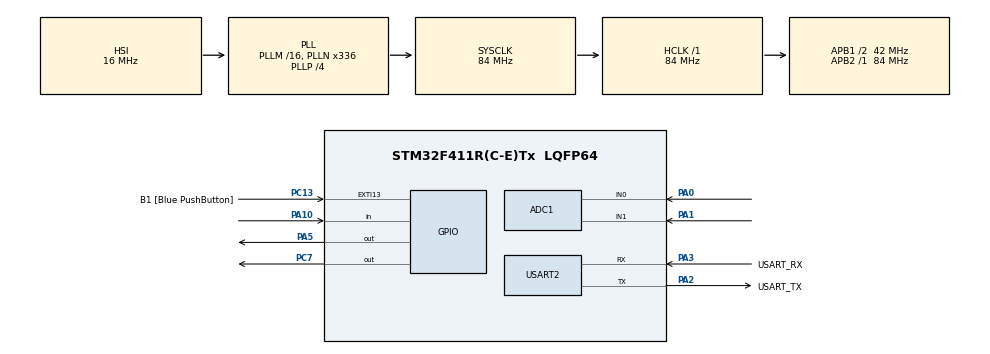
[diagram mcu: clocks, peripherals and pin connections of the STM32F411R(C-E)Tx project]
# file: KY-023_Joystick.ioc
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ADC1.Channel-3\#ChannelRegularConversion=ADC_CHANNEL_1
ADC1.NbrOfConversionFlag=1
ADC1.Rank-3\#ChannelRegularConversion=1
ADC1.SamplingTime-3\#ChannelRegularConversion=ADC_SAMPLETIME_3CYCLES
ADC1.master=1
Mcu.Family=STM32F4
Mcu.Name=STM32F411R(C-E)Tx
Mcu.Package=LQFP64
NVIC.PriorityGroup=NVIC_PRIORITYGROUP_0
PA0-WKUP.Signal=ADCx_IN0
PA1.Signal=ADCx_IN1
PA10.GPIO_PuPd=GPIO_PULLUP
PA10.Signal=GPIO_Input
PA13.GPIO_Label=TMS
PA13.Signal=SYS_JTMS-SWDIO
PA14.GPIO_Label=TCK
PA14.Signal=SYS_JTCK-SWCLK
PA2.GPIO_Label=USART_TX
PA2.Mode=Asynchronous
PA2.Signal=USART2_TX
PA3.GPIO_Label=USART_RX
PA3.Mode=Asynchronous
PA3.Signal=USART2_RX
PA5.Signal=GPIO_Output
PB3.Signal=SYS_JTDO-SWO
PC13-ANTI_TAMP.GPIO_Label=B1 [Blue PushButton]
PC13-ANTI_TAMP.GPIO_ModeDefaultEXTI=GPIO_MODE_IT_FALLING
PC13-ANTI_TAMP.Signal=GPXTI13
PC14-OSC32_IN.Mode=LSE-External-Oscillator
PC14-OSC32_IN.Signal=RCC_OSC32_IN
PC15-OSC32_OUT.Mode=LSE-External-Oscillator
PC15-OSC32_OUT.Signal=RCC_OSC32_OUT
PC7.Signal=GPIO_Output
PH0\ -\ OSC_IN.Mode=HSE-External-Clock-Source
PH0\ -\ OSC_IN.Signal=RCC_OSC_IN
PH1\ -\ OSC_OUT.Mode=HSE-External-Clock-Source
PH1\ -\ OSC_OUT.Signal=RCC_OSC_OUT
ProjectManager.HeapSize=0x200
ProjectManager.StackSize=0x400
ProjectManager.TargetToolchain=STM32CubeIDE
RCC.48MHZClocksFreq_Value=84000000
RCC.AHBFreq_Value=84000000
RCC.APB1CLKDivider=RCC_HCLK_DIV2
RCC.APB1Freq_Value=42000000
RCC.APB1TimFreq_Value=84000000
RCC.APB2Freq_Value=84000000
RCC.APB2TimFreq_Value=84000000
RCC.CortexFreq_Value=84000000
RCC.FLatency-AdvancedSettings=FLASH_LATENCY_2
RCC.HCLKFreq_Value=84000000
RCC.HSE_VALUE=8000000
RCC.HSI_VALUE=16000000
RCC.PLLN=336
RCC.PLLP=RCC_PLLP_DIV4
RCC.SYSCLKFreq_VALUE=84000000
RCC.SYSCLKSource=RCC_SYSCLKSOURCE_PLLCLK
RCC.VCOOutputFreq_Value=336000000
SH.ADCx_IN0.0=ADC1_IN0,IN0
SH.ADCx_IN1.0=ADC1_IN1,IN1
TIM3.Period=999
TIM3.Prescaler=95
USART2.VirtualMode=VM_ASYNC
VP_TIM3_VS_ClockSourceINT.Mode=Internal
board=NUCLEO-F411RE

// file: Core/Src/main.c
/* USER CODE BEGIN Header */
/**
 ******************************************************************************
 * @file           : main.c
 * @brief          : Main program body
 ******************************************************************************
 * @attention
 *
 * Copyright (c) 2026 STMicroelectronics.
 * All rights reserved.
 *
 * This software is licensed under terms that can be found in the LICENSE file
 * in the root directory of this software component.
 * If no LICENSE file comes with this software, it is provided AS-IS.
 *
 ******************************************************************************
 */
/* USER CODE END Header */
#include "main.h"

/* USER CODE BEGIN Includes */
#include <stdio.h>   // Для корректной работы sprintf
#include <stdlib.h>  // Для корректной работы abs
/* USER CODE END Includes */

ADC_HandleTypeDef hadc1;
DMA_HandleTypeDef hdma_adc1;

TIM_HandleTypeDef htim3;

UART_HandleTypeDef huart2;

/* USER CODE BEGIN PV */
extern TIM_HandleTypeDef htim3;

//uint16_t adc_buffer[2];  // Массив: adc_buffer[0] - X, adc_buffer[1] - Y
int32_t x_percent = 0;     // Итоговый процент X (-100...100)
int32_t y_percent = 0;     // Итоговый процент Y (-100...100)
uint8_t btn_state = 0;     // Кнопка
char tx_buf[100];          // Буфер для текста (задали четкий размер)

#define DEADZONE 80        // Мертвая зона
/* USER CODE END PV */

void SystemClock_Config(void);
static void MX_GPIO_Init(void);
static void MX_DMA_Init(void);
static void MX_USART2_UART_Init(void);
static void MX_ADC1_Init(void);
static void MX_TIM3_Init(void);

/* USER CODE BEGIN 0 */

uint32_t Read_ADC_Channel(uint32_t channel) {
	ADC_ChannelConfTypeDef sConfig = { 0 };

	sConfig.Channel = channel;
	sConfig.Rank = 1;
	sConfig.SamplingTime = ADC_SAMPLETIME_84CYCLES;

	// Если конфигурация канала не удалась, просто выходим
	if (HAL_ADC_ConfigChannel(&hadc1, &sConfig) != HAL_OK) {
		return 2048; // Возвращаем центр, чтобы не было ложного прыжка в 100%
	}

	HAL_ADC_Start(&hadc1);
	// Задаем жесткий таймаут в 5 миллисекунд. Если АЦП завис — HAL принудительно вернет управление
	if (HAL_ADC_PollForConversion(&hadc1, 5) == HAL_OK) {
		uint32_t val = HAL_ADC_GetValue(&hadc1);
		HAL_ADC_Stop(&hadc1);
		return val;
	}
	HAL_ADC_Stop(&hadc1);
	return 2048; // Если замер не успел, возвращаем центр
}

/* USER CODE END 0 */

int main(void) {
	/* USER CODE BEGIN 1 */
	// 1. Включаем тактирование Порта C и Таймера 3 напрямую в регистрах
	__HAL_RCC_GPIOC_CLK_ENABLE();
	__HAL_RCC_TIM3_CLK_ENABLE();

	// 2. Переводим пин PC7 в режим альтернативной функции (ШИМ таймера)
	GPIOC->MODER &= ~(3 << (7 * 2)); // Очищаем старый режим
	GPIOC->MODER |= (2 << (7 * 2)); // Устанавливаем режим 10 (Alternate function mode)

	// 3. Указываем, что альтернативная функция для PC7 — это именно TIM3 (AF02)
	GPIOC->AFR[0] &= ~(0xF << (7 * 4)); // Очищаем регистр альтернативных функций для пина 7
	GPIOC->AFR[0] |= (2 << (7 * 4));   // Записываем код AF2 (Таймер TIM3)
	/* USER CODE END 1 */

	/* MCU Configuration--------------------------------------------------------*/

	/* Reset of all peripherals, Initializes the Flash interface and the Systick. */
	HAL_Init();

	/* Configure the system clock */
	SystemClock_Config();

	/* Initialize all configured peripherals */
	MX_GPIO_Init();
	MX_DMA_Init();
	MX_USART2_UART_Init();
	MX_ADC1_Init();
	MX_TIM3_Init();

	/* USER CODE BEGIN 2 */
	HAL_ADC_Start(&hadc1);

	// Запускаем генерацию ШИМ на втором канале таймера 3
//	HAL_TIM_PWM_Start(&htim3, TIM_CHANNEL_1);
	HAL_TIM_PWM_Start(&htim3, TIM_CHANNEL_2);
	/* USER CODE END 2 */

	/* Infinite loop */
	while (1) {

		/* USER CODE BEGIN 3 */
		// Принудительно переводим пин PC7 в режим обычного выхода и включаем его на 100%
		HAL_GPIO_WritePin(GPIOC, GPIO_PIN_7, GPIO_PIN_SET);

		int32_t raw_x = (int32_t) Read_ADC_Channel(ADC_CHANNEL_0) - 2048; // Пин PA0 (A0)
		int32_t raw_y = (int32_t) Read_ADC_Channel(ADC_CHANNEL_1) - 2048; // Пин PA1 (A1)
		int32_t max_range = 2048 - DEADZONE;

		// 2. Расчет процентов оси X
		if (raw_x > -DEADZONE && raw_x < DEADZONE)
			x_percent = 0;
		else if (raw_x >= DEADZONE)
			x_percent = ((raw_x - DEADZONE) * 100) / max_range;
		else
			x_percent = ((raw_x + DEADZONE) * 100) / max_range;

		// 3. Расчет процентов оси Y
		if (raw_y > -DEADZONE && raw_y < DEADZONE)
			y_percent = 0;
		else if (raw_y >= DEADZONE)
			y_percent = ((raw_y - DEADZONE) * 100) / max_range;
		else
			y_percent = ((raw_y + DEADZONE) * 100) / max_range;

		// Жесткое ограничение лимитов [-100, 100] на случай шумов
		if (x_percent > 100)
			x_percent = 100;
		if (x_percent < -100)
			x_percent = -100;
		if (y_percent > 100)
			y_percent = 100;
		if (y_percent < -100)
			y_percent = -100;

		// 4. Опрос кнопки (PA10) и управление встроенным зеленым диодом (оставляем как есть)
		if (HAL_GPIO_ReadPin(GPIOA, GPIO_PIN_10) == GPIO_PIN_RESET) {
			btn_state = 1;
			HAL_GPIO_WritePin(GPIOA, GPIO_PIN_5, GPIO_PIN_SET);
		} else {
			btn_state = 0;
			HAL_GPIO_WritePin(GPIOA, GPIO_PIN_5, GPIO_PIN_RESET);
		}

//		// 5. НАДЕЖНОЕ ПРОГРАММНОЕ УПРАВЛЕНИЕ ВЫЖИВШИМ КРАСНЫМ СВЕТОДИОДОМ
//		// Если джойстик отклонен влево или вправо (по оси X) более чем на 30%
//		if (abs(x_percent) > 30) {
//			// Подаем 3.3В на ножку PC7 — красный светодиод ярко загорается!
//			HAL_GPIO_WritePin(GPIOC, GPIO_PIN_7, GPIO_PIN_SET);
//		} else {
//			// Джойстик в центре (внутри мертвой зоны) — полностью гасим светодиод
//			HAL_GPIO_WritePin(GPIOC, GPIO_PIN_7, GPIO_PIN_RESET);
//		}
//
		// 5. ПЛАВНОЕ УПРАВЛЕНИЕ ШИМ-МОДУЛЕМ (Переводим проценты в яркость)
		// Превращаем проценты оси X (-100...100%) в шаги таймера от 0 до 999
		uint32_t pwm_x = (abs(x_percent) * 999) / 100;

		// Записываем значение в регистр сравнения второго канала таймера (пин PC7)
		__HAL_TIM_SET_COMPARE(&htim3, TIM_CHANNEL_2, pwm_x);

		// 6. Вывод рабочих данных в UART (оставляем как есть)
		int len = sprintf(tx_buf, "X: %4ld%% | Y: %4ld%% | Button: %d\r\n",
				x_percent, y_percent, btn_state);
		HAL_UART_Transmit(&huart2, (uint8_t*) tx_buf, len, HAL_MAX_DELAY);

		HAL_Delay(100);
	}
	/* USER CODE END 3 */

}

void SystemClock_Config(void) {
	RCC_OscInitTypeDef RCC_OscInitStruct = { 0 };
	RCC_ClkInitTypeDef RCC_ClkInitStruct = { 0 };

	/** Configure the main internal regulator output voltage
	 */
	__HAL_RCC_PWR_CLK_ENABLE();
	__HAL_PWR_VOLTAGESCALING_CONFIG(PWR_REGULATOR_VOLTAGE_SCALE1);

	/** Initializes the RCC Oscillators according to the specified parameters
	 * in the RCC_OscInitTypeDef structure.
	 */
	RCC_OscInitStruct.OscillatorType = RCC_OSCILLATORTYPE_HSI;
	RCC_OscInitStruct.HSIState = RCC_HSI_ON;
	RCC_OscInitStruct.HSICalibrationValue = RCC_HSICALIBRATION_DEFAULT;
	RCC_OscInitStruct.PLL.PLLState = RCC_PLL_ON;
	RCC_OscInitStruct.PLL.PLLSource = RCC_PLLSOURCE_HSI;
	RCC_OscInitStruct.PLL.PLLM = 16;
	RCC_OscInitStruct.PLL.PLLN = 336;
	RCC_OscInitStruct.PLL.PLLP = RCC_PLLP_DIV4;
	RCC_OscInitStruct.PLL.PLLQ = 4;
	if (HAL_RCC_OscConfig(&RCC_OscInitStruct) != HAL_OK) {
		Error_Handler();
	}

	/** Initializes the CPU, AHB and APB buses clocks
	 */
	RCC_ClkInitStruct.ClockType = RCC_CLOCKTYPE_HCLK | RCC_CLOCKTYPE_SYSCLK
			| RCC_CLOCKTYPE_PCLK1 | RCC_CLOCKTYPE_PCLK2;
	RCC_ClkInitStruct.SYSCLKSource = RCC_SYSCLKSOURCE_PLLCLK;
	RCC_ClkInitStruct.AHBCLKDivider = RCC_SYSCLK_DIV1;
	RCC_ClkInitStruct.APB1CLKDivider = RCC_HCLK_DIV2;
	RCC_ClkInitStruct.APB2CLKDivider = RCC_HCLK_DIV1;

	if (HAL_RCC_ClockConfig(&RCC_ClkInitStruct, FLASH_LATENCY_2) != HAL_OK) {
		Error_Handler();
	}
}

static void MX_ADC1_Init(void) {

	ADC_ChannelConfTypeDef sConfig = { 0 };

	/** Configure the global features of the ADC (Clock, Resolution, Data Alignment and number of conversion)
	 */
	hadc1.Instance = ADC1;
	hadc1.Init.ClockPrescaler = ADC_CLOCK_SYNC_PCLK_DIV4;
	hadc1.Init.Resolution = ADC_RESOLUTION_12B;
	hadc1.Init.ScanConvMode = ENABLE;
	hadc1.Init.ContinuousConvMode = DISABLE;
	hadc1.Init.DiscontinuousConvMode = DISABLE;
	hadc1.Init.ExternalTrigConvEdge = ADC_EXTERNALTRIGCONVEDGE_NONE;
	hadc1.Init.ExternalTrigConv = ADC_SOFTWARE_START;
	hadc1.Init.DataAlign = ADC_DATAALIGN_RIGHT;
	hadc1.Init.NbrOfConversion = 2;
	hadc1.Init.DMAContinuousRequests = DISABLE;
	hadc1.Init.EOCSelection = ADC_EOC_SINGLE_CONV;
	if (HAL_ADC_Init(&hadc1) != HAL_OK) {
		Error_Handler();
	}

	/** Configure for the selected ADC regular channel its corresponding rank in the sequencer and its sample time.
	 */
	sConfig.Channel = ADC_CHANNEL_0;
	sConfig.Rank = 1;
	sConfig.SamplingTime = ADC_SAMPLETIME_84CYCLES;
	if (HAL_ADC_ConfigChannel(&hadc1, &sConfig) != HAL_OK) {
		Error_Handler();
	}

	/** Configure for the selected ADC regular channel its corresponding rank in the sequencer and its sample time.
	 */
	sConfig.Channel = ADC_CHANNEL_1;
	sConfig.Rank = 2;
	if (HAL_ADC_ConfigChannel(&hadc1, &sConfig) != HAL_OK) {
		Error_Handler();
	}

}

static void MX_TIM3_Init(void) {

	TIM_ClockConfigTypeDef sClockSourceConfig = { 0 };
	TIM_MasterConfigTypeDef sMasterConfig = { 0 };
	TIM_OC_InitTypeDef sConfigOC = { 0 };

	htim3.Instance = TIM3;
	htim3.Init.Prescaler = 95;
	htim3.Init.CounterMode = TIM_COUNTERMODE_UP;
	htim3.Init.Period = 999;
	htim3.Init.ClockDivision = TIM_CLOCKDIVISION_DIV1;
	htim3.Init.AutoReloadPreload = TIM_AUTORELOAD_PRELOAD_DISABLE;
	if (HAL_TIM_Base_Init(&htim3) != HAL_OK) {
		Error_Handler();
	}
	sClockSourceConfig.ClockSource = TIM_CLOCKSOURCE_INTERNAL;
	if (HAL_TIM_ConfigClockSource(&htim3, &sClockSourceConfig) != HAL_OK) {
		Error_Handler();
	}
	if (HAL_TIM_PWM_Init(&htim3) != HAL_OK) {
		Error_Handler();
	}
	sMasterConfig.MasterOutputTrigger = TIM_TRGO_RESET;
	sMasterConfig.MasterSlaveMode = TIM_MASTERSLAVEMODE_DISABLE;
	if (HAL_TIMEx_MasterConfigSynchronization(&htim3, &sMasterConfig)
			!= HAL_OK) {
		Error_Handler();
	}
	sConfigOC.OCMode = TIM_OCMODE_PWM1;
	sConfigOC.Pulse = 0;
	sConfigOC.OCPolarity = TIM_OCPOLARITY_HIGH;
	sConfigOC.OCFastMode = TIM_OCFAST_DISABLE;
	if (HAL_TIM_PWM_ConfigChannel(&htim3, &sConfigOC, TIM_CHANNEL_1)
			!= HAL_OK) {
		Error_Handler();
	}
	if (HAL_TIM_PWM_ConfigChannel(&htim3, &sConfigOC, TIM_CHANNEL_2)
			!= HAL_OK) {
		Error_Handler();
	}
	HAL_TIM_MspPostInit(&htim3);

}

static void MX_USART2_UART_Init(void) {

	huart2.Instance = USART2;
	huart2.Init.BaudRate = 115200;
	huart2.Init.WordLength = UART_WORDLENGTH_8B;
	huart2.Init.StopBits = UART_STOPBITS_1;
	huart2.Init.Parity = UART_PARITY_NONE;
	huart2.Init.Mode = UART_MODE_TX_RX;
	huart2.Init.HwFlowCtl = UART_HWCONTROL_NONE;
	huart2.Init.OverSampling = UART_OVERSAMPLING_16;
	if (HAL_UART_Init(&huart2) != HAL_OK) {
		Error_Handler();
	}

}

static void MX_DMA_Init(void) {

	/* DMA controller clock enable */
	__HAL_RCC_DMA2_CLK_ENABLE();

	/* DMA interrupt init */
	/* DMA2_Stream0_IRQn interrupt configuration */
	HAL_NVIC_SetPriority(DMA2_Stream0_IRQn, 0, 0);
	HAL_NVIC_EnableIRQ(DMA2_Stream0_IRQn);

}

static void MX_GPIO_Init(void) {
	GPIO_InitTypeDef GPIO_InitStruct = { 0 };

	/* GPIO Ports Clock Enable */
	__HAL_RCC_GPIOC_CLK_ENABLE();
	__HAL_RCC_GPIOH_CLK_ENABLE();
	__HAL_RCC_GPIOA_CLK_ENABLE();
	__HAL_RCC_GPIOB_CLK_ENABLE();

	/*Configure GPIO pin Output Level */
	HAL_GPIO_WritePin(LD2_GPIO_Port, LD2_Pin, GPIO_PIN_RESET);

	/*Configure GPIO pin : B1_Pin */
	GPIO_InitStruct.Pin = B1_Pin;
	GPIO_InitStruct.Mode = GPIO_MODE_IT_FALLING;
	GPIO_InitStruct.Pull = GPIO_NOPULL;
	HAL_GPIO_Init(B1_GPIO_Port, &GPIO_InitStruct);

	/*Configure GPIO pin : LD2_Pin */
	GPIO_InitStruct.Pin = LD2_Pin;
	GPIO_InitStruct.Mode = GPIO_MODE_OUTPUT_PP;
	GPIO_InitStruct.Pull = GPIO_NOPULL;
	GPIO_InitStruct.Speed = GPIO_SPEED_FREQ_LOW;
	HAL_GPIO_Init(LD2_GPIO_Port, &GPIO_InitStruct);

	/*Configure GPIO pin : PA10 */
	GPIO_InitStruct.Pin = GPIO_PIN_10;
	GPIO_InitStruct.Mode = GPIO_MODE_INPUT;
	GPIO_InitStruct.Pull = GPIO_PULLUP;
	HAL_GPIO_Init(GPIOA, &GPIO_InitStruct);

}

void Error_Handler(void) {
	__disable_irq();
	while (1) {
	}
}
